# ATSAMC21N17A register map
Registers are 32-bit, access not given, no defined reset value unless marked. A register's access mark holds for its fields unless they carry their own. Addresses are absolute; registers are grouped by the start of their names; [hi:lo] are bit positions; {n}, {i} and the like mark numbered series; 'fields as' and 'values as' point back to an identical list.

## TCC1
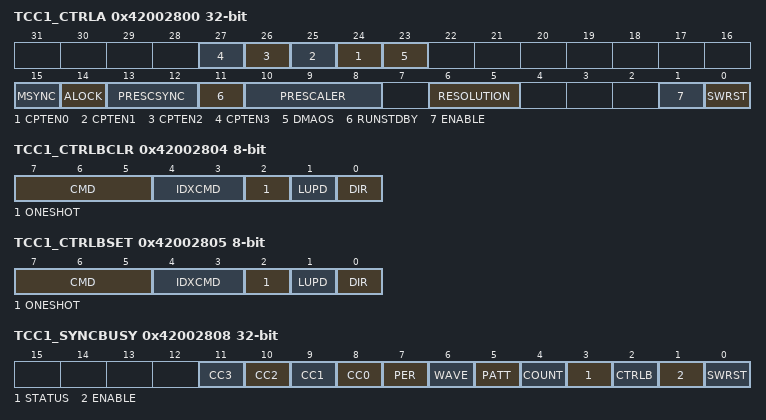
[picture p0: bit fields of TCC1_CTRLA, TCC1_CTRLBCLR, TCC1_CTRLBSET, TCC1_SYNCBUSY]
0x42002800 TCC1_CTRLA — Control A
  [n+24] CPTEN{n} (n=0..3), [23] DMAOS, [15] MSYNC, [14] ALOCK, [13:12] PRESCSYNC, [11] RUNSTDBY, [10:8] PRESCALER, [6:5] RESOLUTION, [1] ENABLE, [0] SWRST
0x42002804 TCC1_CTRLBCLR 8-bit — Control B Clear
  [7:5] CMD, [4:3] IDXCMD, [2] ONESHOT, [1] LUPD, [0] DIR
0x42002805 TCC1_CTRLBSET 8-bit — Control B Set
  [7:5] CMD, [4:3] IDXCMD, [2] ONESHOT, [1] LUPD, [0] DIR
0x42002808 TCC1_SYNCBUSY — Synchronization Busy
  [n+8] CC{n} (n=0..3), [7] PER, [6] WAVE, [5] PATT, [4] COUNT, [3] STATUS, [2] CTRLB, [1] ENABLE, [0] SWRST
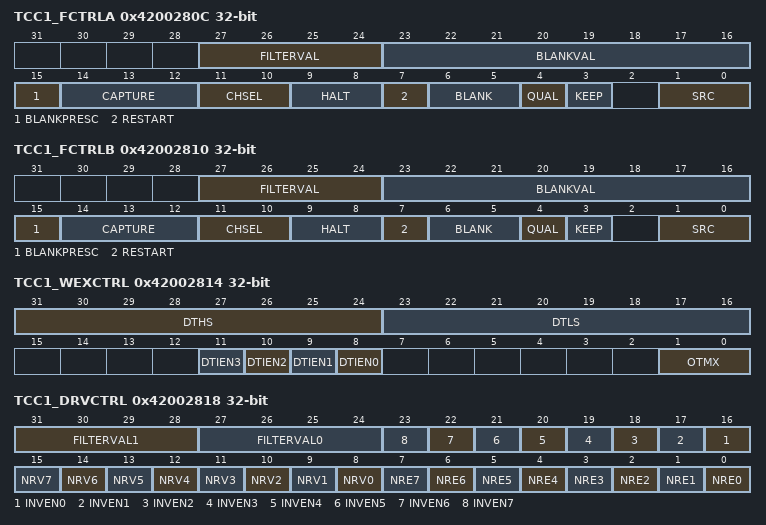
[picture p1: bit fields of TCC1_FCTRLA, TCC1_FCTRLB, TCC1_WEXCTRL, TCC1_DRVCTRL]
0x4200280C TCC1_FCTRLA — Recoverable Fault A Configuration
  [27:24] FILTERVAL, [23:16] BLANKVAL, [15] BLANKPRESC, [14:12] CAPTURE, [11:10] CHSEL, [9:8] HALT, [7] RESTART, [6:5] BLANK, [4] QUAL, [3] KEEP, [1:0] SRC
0x42002810 TCC1_FCTRLB — Recoverable Fault B Configuration
  fields as TCC1_FCTRLA
0x42002814 TCC1_WEXCTRL — Waveform Extension Configuration
  [31:24] DTHS, [23:16] DTLS, [n+8] DTIEN{n} (n=0..3), [1:0] OTMX
0x42002818 TCC1_DRVCTRL — Driver Control
  [31:28] FILTERVAL1, [27:24] FILTERVAL0, [n+16] INVEN{n} (n=0..7), [n+8] NRV{n} (n=0..7), [n] NRE{n} (n=0..7)
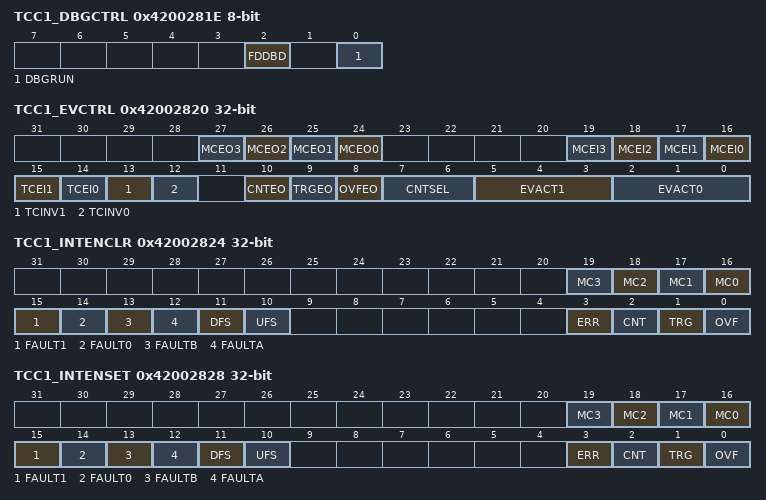
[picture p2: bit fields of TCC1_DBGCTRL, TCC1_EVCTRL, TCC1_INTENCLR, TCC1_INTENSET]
0x4200281E TCC1_DBGCTRL 8-bit — Debug Control
  [2] FDDBD, [0] DBGRUN
0x42002820 TCC1_EVCTRL — Event Control
  [n+24] MCEO{n} (n=0..3), [n+16] MCEI{n} (n=0..3), [15] TCEI1, [14] TCEI0, [13] TCINV1, [12] TCINV0, [10] CNTEO, [9] TRGEO, [8] OVFEO, [7:6] CNTSEL, [5:3] EVACT1, [2:0] EVACT0
0x42002824 TCC1_INTENCLR — Interrupt Enable Clear
  [n+16] MC{n} (n=0..3), [15] FAULT1, [14] FAULT0, [13] FAULTB, [12] FAULTA, [11] DFS, [10] UFS, [3] ERR, [2] CNT, [1] TRG, [0] OVF
0x42002828 TCC1_INTENSET — Interrupt Enable Set
  fields as TCC1_INTENCLR
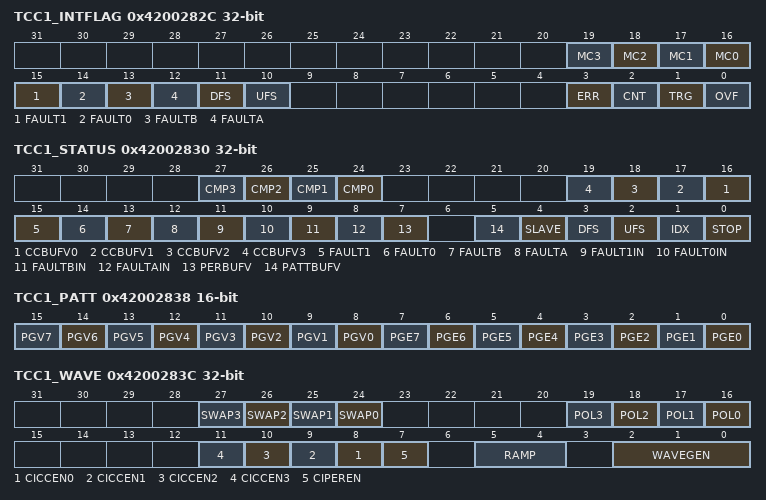
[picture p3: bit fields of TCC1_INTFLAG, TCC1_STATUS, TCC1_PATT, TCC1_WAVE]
0x4200282C TCC1_INTFLAG — Interrupt Flag Status and Clear
  fields as TCC1_INTENCLR
0x42002830 TCC1_STATUS — Status
  [n+24] CMP{n} (n=0..3), [n+16] CCBUFV{n} (n=0..3), [15] FAULT1, [14] FAULT0, [13] FAULTB, [12] FAULTA, [11] FAULT1IN, [10] FAULT0IN, [9] FAULTBIN, [8] FAULTAIN, [7] PERBUFV, [5] PATTBUFV, [4] SLAVE, [3] DFS, [2] UFS, [1] IDX, [0] STOP
0x42002834 TCC1_COUNT — Count
  [23:6] COUNT, [23:5] COUNT, [23:4] COUNT, [23:0] COUNT
0x42002838 TCC1_PATT 16-bit — Pattern
  [n+8] PGV{n} (n=0..7), [n] PGE{n} (n=0..7)
0x4200283C TCC1_WAVE — Waveform Control
  [n+24] SWAP{n} (n=0..3), [n+16] POL{n} (n=0..3), [n+8] CICCEN{n} (n=0..3), [7] CIPEREN, [5:4] RAMP, [2:0] WAVEGEN
0x42002840 TCC1_PER — Period
  [23:6] PER, [23:5] PER, [23:4] PER, [3:0] DITHER, [4:0] DITHER, [5:0] DITHER, [23:0] PER
0x42002844 TCC1_CC — Compare and Capture
  [23:6] CC, [23:5] CC, [23:4] CC, [3:0] DITHER, [4:0] DITHER, [5:0] DITHER, [23:0] CC
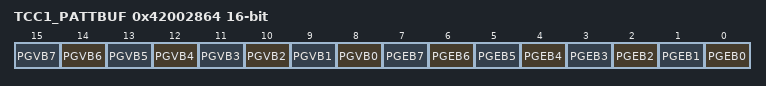
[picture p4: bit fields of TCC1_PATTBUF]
0x42002864 TCC1_PATTBUF 16-bit — Pattern Buffer
  [n+8] PGVB{n} (n=0..7), [n] PGEB{n} (n=0..7)
0x4200286C TCC1_PERBUF — Period Buffer
  [23:6] PERBUF, [23:5] PERBUF, [23:4] PERBUF, [3:0] DITHERBUF, [4:0] DITHERBUF, [5:0] DITHERBUF, [23:0] PERBUF
0x42002870 TCC1_CCBUF — Compare and Capture Buffer
  [23:6] CCBUF, [23:5] CCBUF, [23:4] DITHERBUF, [3:0] CCBUF, [4:0] DITHERBUF, [5:0] DITHERBUF, [23:0] CCBUF

## TCC2
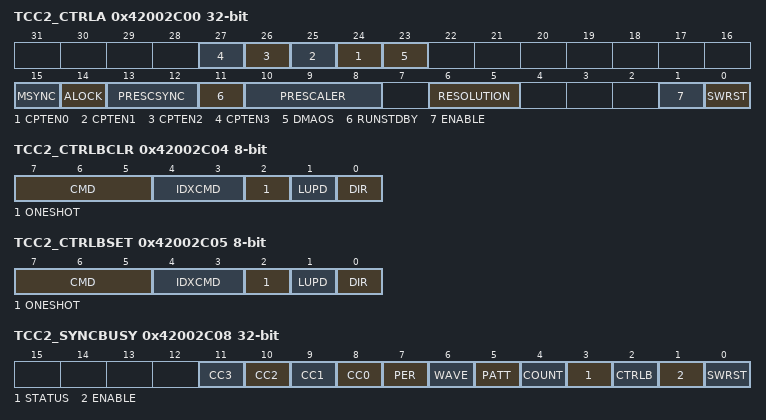
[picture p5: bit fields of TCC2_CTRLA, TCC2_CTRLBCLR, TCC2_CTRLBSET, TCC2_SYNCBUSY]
0x42002C00 TCC2_CTRLA — Control A
  [n+24] CPTEN{n} (n=0..3), [23] DMAOS, [15] MSYNC, [14] ALOCK, [13:12] PRESCSYNC, [11] RUNSTDBY, [10:8] PRESCALER, [6:5] RESOLUTION, [1] ENABLE, [0] SWRST
0x42002C04 TCC2_CTRLBCLR 8-bit — Control B Clear
  [7:5] CMD, [4:3] IDXCMD, [2] ONESHOT, [1] LUPD, [0] DIR
0x42002C05 TCC2_CTRLBSET 8-bit — Control B Set
  [7:5] CMD, [4:3] IDXCMD, [2] ONESHOT, [1] LUPD, [0] DIR
0x42002C08 TCC2_SYNCBUSY — Synchronization Busy
  [n+8] CC{n} (n=0..3), [7] PER, [6] WAVE, [5] PATT, [4] COUNT, [3] STATUS, [2] CTRLB, [1] ENABLE, [0] SWRST
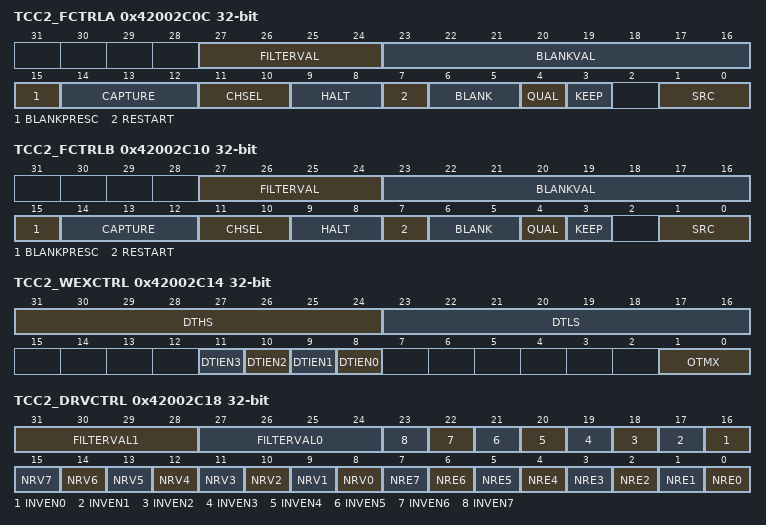
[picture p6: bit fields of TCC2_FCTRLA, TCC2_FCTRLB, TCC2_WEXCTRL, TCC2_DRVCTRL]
0x42002C0C TCC2_FCTRLA — Recoverable Fault A Configuration
  [27:24] FILTERVAL, [23:16] BLANKVAL, [15] BLANKPRESC, [14:12] CAPTURE, [11:10] CHSEL, [9:8] HALT, [7] RESTART, [6:5] BLANK, [4] QUAL, [3] KEEP, [1:0] SRC
0x42002C10 TCC2_FCTRLB — Recoverable Fault B Configuration
  fields as TCC2_FCTRLA
0x42002C14 TCC2_WEXCTRL — Waveform Extension Configuration
  [31:24] DTHS, [23:16] DTLS, [n+8] DTIEN{n} (n=0..3), [1:0] OTMX
0x42002C18 TCC2_DRVCTRL — Driver Control
  [31:28] FILTERVAL1, [27:24] FILTERVAL0, [n+16] INVEN{n} (n=0..7), [n+8] NRV{n} (n=0..7), [n] NRE{n} (n=0..7)
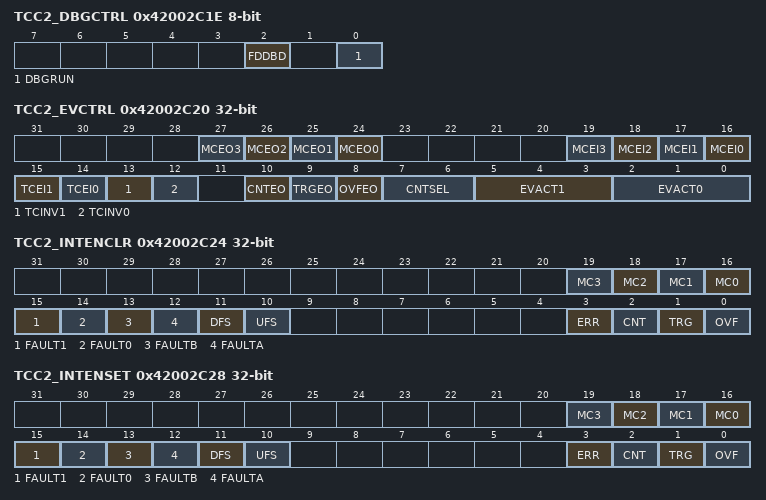
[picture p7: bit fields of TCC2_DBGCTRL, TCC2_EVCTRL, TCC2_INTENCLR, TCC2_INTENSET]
0x42002C1E TCC2_DBGCTRL 8-bit — Debug Control
  [2] FDDBD, [0] DBGRUN
0x42002C20 TCC2_EVCTRL — Event Control
  [n+24] MCEO{n} (n=0..3), [n+16] MCEI{n} (n=0..3), [15] TCEI1, [14] TCEI0, [13] TCINV1, [12] TCINV0, [10] CNTEO, [9] TRGEO, [8] OVFEO, [7:6] CNTSEL, [5:3] EVACT1, [2:0] EVACT0
0x42002C24 TCC2_INTENCLR — Interrupt Enable Clear
  [n+16] MC{n} (n=0..3), [15] FAULT1, [14] FAULT0, [13] FAULTB, [12] FAULTA, [11] DFS, [10] UFS, [3] ERR, [2] CNT, [1] TRG, [0] OVF
0x42002C28 TCC2_INTENSET — Interrupt Enable Set
  fields as TCC2_INTENCLR
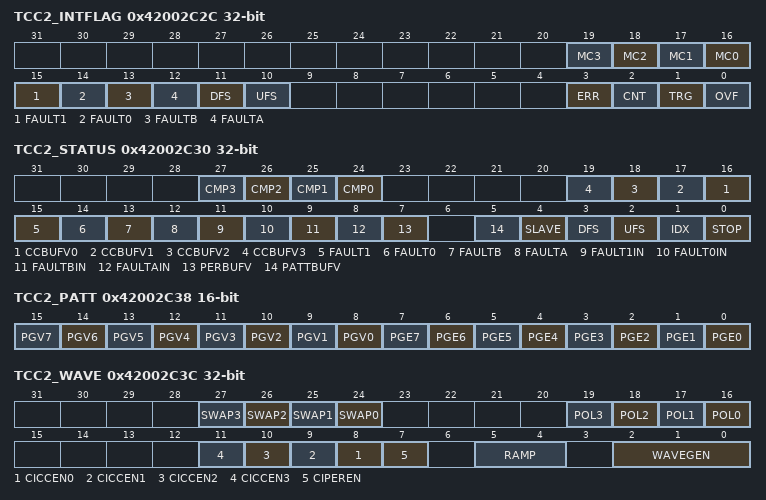
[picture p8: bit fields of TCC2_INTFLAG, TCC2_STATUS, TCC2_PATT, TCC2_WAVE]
0x42002C2C TCC2_INTFLAG — Interrupt Flag Status and Clear
  fields as TCC2_INTENCLR
0x42002C30 TCC2_STATUS — Status
  [n+24] CMP{n} (n=0..3), [n+16] CCBUFV{n} (n=0..3), [15] FAULT1, [14] FAULT0, [13] FAULTB, [12] FAULTA, [11] FAULT1IN, [10] FAULT0IN, [9] FAULTBIN, [8] FAULTAIN, [7] PERBUFV, [5] PATTBUFV, [4] SLAVE, [3] DFS, [2] UFS, [1] IDX, [0] STOP
0x42002C34 TCC2_COUNT — Count
  [23:6] COUNT, [23:5] COUNT, [23:4] COUNT, [23:0] COUNT
0x42002C38 TCC2_PATT 16-bit — Pattern
  [n+8] PGV{n} (n=0..7), [n] PGE{n} (n=0..7)
0x42002C3C TCC2_WAVE — Waveform Control
  [n+24] SWAP{n} (n=0..3), [n+16] POL{n} (n=0..3), [n+8] CICCEN{n} (n=0..3), [7] CIPEREN, [5:4] RAMP, [2:0] WAVEGEN
0x42002C40 TCC2_PER — Period
  [23:6] PER, [23:5] PER, [23:4] PER, [3:0] DITHER, [4:0] DITHER, [5:0] DITHER, [23:0] PER
0x42002C44 TCC2_CC — Compare and Capture
  [23:6] CC, [23:5] CC, [23:4] CC, [3:0] DITHER, [4:0] DITHER, [5:0] DITHER, [23:0] CC
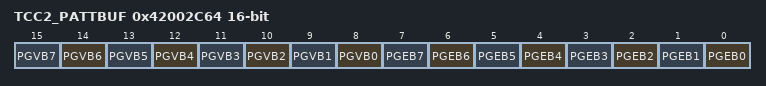
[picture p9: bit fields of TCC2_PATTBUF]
0x42002C64 TCC2_PATTBUF 16-bit — Pattern Buffer
  [n+8] PGVB{n} (n=0..7), [n] PGEB{n} (n=0..7)
0x42002C6C TCC2_PERBUF — Period Buffer
  [23:6] PERBUF, [23:5] PERBUF, [23:4] PERBUF, [3:0] DITHERBUF, [4:0] DITHERBUF, [5:0] DITHERBUF, [23:0] PERBUF
0x42002C70 TCC2_CCBUF — Compare and Capture Buffer
  [23:6] CCBUF, [23:5] CCBUF, [23:4] DITHERBUF, [3:0] CCBUF, [4:0] DITHERBUF, [5:0] DITHERBUF, [23:0] CCBUF
